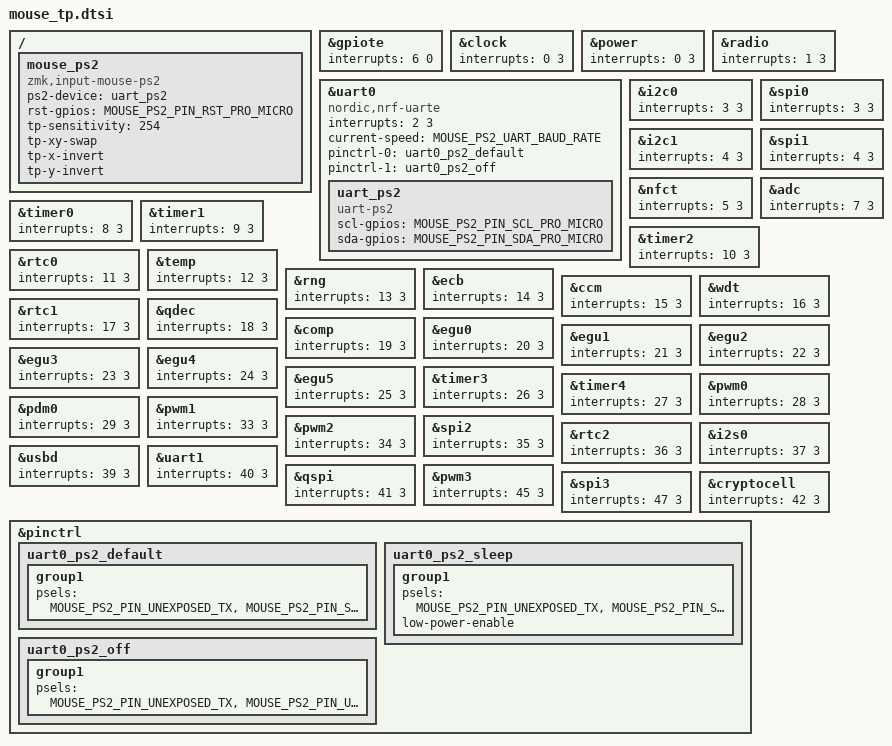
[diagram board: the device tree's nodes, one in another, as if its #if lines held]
#ifdef HAS_MOUSE_TP
  #include <dt-bindings/zmk/mouse.h>
  #include <dt-bindings/zmk/mouse_settings.h>
  #include <behaviors/mouse_keys.dtsi>
  #include <behaviors/mouse_setting.dtsi>
/*
 * PS/2 Mouse / Trackpoint - User Configuration
 *
 * Enable PS/2 drivers on this side of the keyboard.
 * It MUST be the central half. If you connected your TP or mouse to the
 * left side, then move the following content to `your_keyboard_left.overlay`
 *
 * You also need to adjust `Kconfig.defconfig` and configure that this side
 * is the central side.
 *
 */

#define MOUSE_PS2_DRIVER_UART


// Configure the SCL and SDA pins using the`&pro_micro` notation.
//
// If possible, try to choose the blue high frequency pins to avoid
// bluetooth interference.
//
// It will still work even if you pick low frequency pins, but there is a risk
// that the trackpoint could cause bluetooth interference.
//
// On the nice!nano documentation these are green DX pins:
// https://nicekeyboards.com/docs/nice-nano/pinout-schematic
//
// The ideal pins are...
//   - D1 and D0 for clock and data, because they are high frequency.
//   - D8, D9, D16 or D10 for the trackpoint reset pin, because it doesn't
//     need to be high frequency (only needed if you are not using a reset
//     circuit)
//
//RP2040 mod kazubu
// clock gp23 -> 16
// data  gp22 -> 15

// But on the yk_do52pro keyboard the trackpoint is connected to 16 and 15 
// in my I swapped clock and data to be compatible with rp2040 pioj
#define MOUSE_PS2_PIN_SCL_PRO_MICRO <&pro_micro 16 GPIO_ACTIVE_HIGH>
#define MOUSE_PS2_PIN_SDA_PRO_MICRO <&pro_micro 15 GPIO_ACTIVE_HIGH>

// Configure the Power-On-Reset pin
//
// Uncomment and configure this pin if you have an extra free pin and want the
// controller to perform the Power-On-Reset sequence, which many trackpoints
// require.
//
// You don't need this if you are not using a trackpoint or if you have a
// trackpoint reset circuit.
//
// It's ok to use a low-frequency pin for this.
//yk_do52pro has reset circuit
//#define MOUSE_PS2_PIN_RST_PRO_MICRO <&pro_micro 9 GPIO_ACTIVE_HIGH>


// Configure SDA pin using the pinctrl notation
//
// Now configure SDA pin using the pinctrl notation. Make sure to use the same
// pin as in the pro micro notation, but convert it to the pinctrl notation.
//
// For the nice!nano you can find it on their pinout schematic, next to the
// pins, in the blue or violet boxes, with a format like `PX.YY` (P0.09).
//
// Enter it like `X, Y` without leading zeroes.
//h
// Examples:
//      D1  - P0.06: 0, 6
// 		D0  - P0.08: 0, 8
//		D15 - P1.13: 1, 13
//		D16 - P0.10: 0, 10
//		D10 - P0.09: 0, 9
//
// We don't define the SCL pin, because UART uses a baud rate instead of
// a clock pin.
#define MOUSE_PS2_PIN_SDA_PINCTRL <NRF_PSEL(UART_RX, 1, 13)>

// Configure UART BAUD Rate
//
// TLDR WARNING:
// Most likely you won't need to adjust this. So leave it at the default value
// of 14,400 and test if your mouse or trackpoint works.
//
// If it doesn't work, try using the GPIO version of the driver. If it works
// with the GPIO driver, then try using the UART driver with the BAUD rates
// 19,200 and 9,600.
//
// So far, all the trackpoints, which the community tested, worked with the
// 14,400 rate.
//
// Explanation what this is:
//
// PS/2 uses a clock pin to syncronize data transmissions. UART on the
// other hand uses a pre-defined frequency (baud rate).
//
// Fortunately, one of the available baud rates is very close to the
// frequency used in IBM/Lenovo trackpoints.
//
// You can find other configurable baud rates here:
// https://docs.zephyrproject.org/latest/build/dts/api/bindings/serial/nordic,nrf-uarte.html
//
// You can also measure the frequency of your mouse/TP using a $5 logic
// analyzer from AliExpress.
//
// Actual frequency of PS/2 trackpoint: 67us
// Corresponding baud rate: 14,925
//
// Closest available baud rate in zephyr: 14,400
// Corresponding cycle length: 69.44 microseconds
//
// Calculations:
//
// Convert cycle length in microseconds into baud:
// 1 / PS2_CYCLE_LENGTH * 1000000 =  BAUD
// 1 / 67 * 1000000 = 14,925 BAUD
//
// Convert baud into cycle length:
// 1 / BAUD * 1000000 = CYCLE_LEN (in microseconds)
// 1 / 14400 * 1000000 = 69.44
//
// Most likely values
//
// The PS/2 protocol specifies that devices must use a clock line
// frequency in the range of 10 - 16.7 kHz.
//
// Most trackpoints seem to operate at around 14-15kHz.
//
// Therefore, the most likely values to try are:
//   - 14400 ( 69 us cycle length   /   14.5kHz)
//   -  9600 (100 us cycle length   /   10.0kHz)
//   - 19200 ( 52 us cycle length   /   19kHz)
#define MOUSE_PS2_UART_BAUD_RATE <14400>


/*
 * PS/2 Mouse / Trackpoint - User Configuration if NOT using nice!nano
 *
 * WARNING: Do NOT change this if you are using a nice!nano v2 or clone.
 */

// Unexposed UART pins
// In UART two different pins are used for receiving and transmitting, but PS/2
// uses the same pin for both.
//
// The UART config still requires both pins to be configured. So we use one of
// the nrf52 pins that are not exposed on the nice!nano board.
//
// Do NOT change these if you are using a nice!nano (or a clone of it)
#define MOUSE_PS2_PIN_UNEXPOSED_TX <NRF_PSEL(UART_TX, 0, 27)>
#define MOUSE_PS2_PIN_UNEXPOSED_RX <NRF_PSEL(UART_RX, 0, 28)>


// Adjust GPIO interrupt priority to the highest level.
//
// IMPORTANT TLDR:
// If you are using the nice_nano_v2 board, you don't need to make changes to
// the config below and can leave it as it is.
//
// Explanation of these settings:
//
// PS/2 events must be processed within 30-50us, but frequently bluetooth and
// other interrupts take longer to finish.
//
// Therefore we change the default GPIO priority to the highest level (0) and
// demote all BT interrupt priorities by one level using the kconfig settings:
// - CONFIG_BT_CTLR_LLL_PRIO 1
// - CONFIG_BT_CTLR_ULL_HIGH_PRIO 2
// - CONFIG_BT_CTLR_ULL_LOW_PRIOCONFIG 2
//
// These config options are enabled automatically by the PS2 UART and GPIO
// drivers... so you don't have to enable them manually.
//
// Then we lower the interrupt priority of all other devices by 2 levels using
// the devicetree config below.
//
// This allows the PS/2 interrupts to be triggered faster and reduces
// transmission errors.
//
// If you are using the nice_nano_v2 board, you can reuse my config below.
//
// Otherwise, you can generate the interrupt overrides using this script:
// https://github.com/infused-kim/kb_zmk_ps2_mouse_trackpoint_driver/blob/main/scripts/gen_interrupt_priority_overrides.py
//
// Make sure to do it on a zephyr.dts where the interrupts have not been
// adjusted yet (i.e. a config that doesn't have the the following options
// enabled).
//
// If you are building using a toolchain you can find the zephyr.dts in the
// build directory, which by default is: `app/build/zephyr/zephyr.dts`
//
// If you are building using the github actions, copy the output of the build
// step `xxxx_right - nice_nano_v2 Devicetree file` into a file and run the
// script on it.

// gpiote should have the highest interrupt priority (0)
&gpiote {
    interrupts = < 6 0 >;
};



// All other priorities should be two levels lower than their defaults
// (which is usually 1 and should be demoted to 3)
&clock {
    interrupts = < 0 3 >;
};

&power {
    interrupts = < 0 3 >;
};

&radio {
    interrupts = < 1 3 >;
};

&uart0 {
    interrupts = < 2 3 >;
};

&i2c0 {
    interrupts = < 3 3 >;
};

&spi0 {
    interrupts = < 3 3 >;
};

&i2c1 {
    interrupts = < 4 3 >;
};

&spi1 {
    interrupts = < 4 3 >;
};

&nfct {
    interrupts = < 5 3 >;
};

&adc {
    interrupts = < 7 3 >;
};

&timer0 {
    interrupts = < 8 3 >;
};

&timer1 {
    interrupts = < 9 3 >;
};

&timer2 {
    interrupts = < 10 3 >;
};

&rtc0 {
    interrupts = < 11 3 >;
};

&temp {
    interrupts = < 12 3 >;
};

&rng {
    interrupts = < 13 3 >;
};

&ecb {
    interrupts = < 14 3 >;
};

&ccm {
    interrupts = < 15 3 >;
};

&wdt {
    interrupts = < 16 3 >;
};

&rtc1 {
    interrupts = < 17 3 >;
};

&qdec {
    interrupts = < 18 3 >;
};

&comp {
    interrupts = < 19 3 >;
};

&egu0 {
    interrupts = < 20 3 >;
};

&egu1 {
    interrupts = < 21 3 >;
};

&egu2 {
    interrupts = < 22 3 >;
};

&egu3 {
    interrupts = < 23 3 >;
};

&egu4 {
    interrupts = < 24 3 >;
};

&egu5 {
    interrupts = < 25 3 >;
};

&timer3 {
    interrupts = < 26 3 >;
};

&timer4 {
    interrupts = < 27 3 >;
};

&pwm0 {
    interrupts = < 28 3 >;
};

&pdm0 {
    interrupts = < 29 3 >;
};

&pwm1 {
    interrupts = < 33 3 >;
};

&pwm2 {
    interrupts = < 34 3 >;
};

&spi2 {
    interrupts = < 35 3 >;
};

&rtc2 {
    interrupts = < 36 3 >;
};

&i2s0 {
    interrupts = < 37 3 >;
};

&usbd {
    interrupts = < 39 3 >;
};

&uart1 {
    interrupts = < 40 3 >;
};

&qspi {
    interrupts = < 41 3 >;
};

&pwm3 {
    interrupts = < 45 3 >;
};

&spi3 {
    interrupts = < 47 3 >;
};

&cryptocell {
    interrupts = < 42 3 >;
};

// This define can be used in the keymap file to check whether the device tree
// configs in this file are present to void build errors on the side that does
// not have the mouse or TP
#define MOUSE_PS2_DT_PRESENT

&pinctrl {
	// This pinctrl state is used for receiving
	// For `UART_TX`, set an unused and unexposed pin
	// For `UART_RX`, set the PS/2 SDA pin number
	uart0_ps2_default: uart0_ps2_default {
		group1 {
			psels = MOUSE_PS2_PIN_UNEXPOSED_TX,
					MOUSE_PS2_PIN_SDA_PINCTRL;
		};
	};

	// Set this to the same pins as uart0_ps2_default
	uart0_ps2_sleep: uart0_ps2_sleep {
		group1 {
			psels = MOUSE_PS2_PIN_UNEXPOSED_TX,
					MOUSE_PS2_PIN_SDA_PINCTRL;
			low-power-enable;
		};
	};

	// The nrf52 UART controller is not compatible with the PS/2
	// transmission frame. So the PS/2 UART driver doesn't use UART for
	// transmissions and instead use GPIO bit-banging.
	//
	// When the driver switches to transmit mode, it frees up the SDA pin by
    // switching the UART controller to unexposed/unused pins.
	//
	// Then it configures the GPIO controller to use the SCL and SDA pins
	uart0_ps2_off: uart0_ps2_off {
		group1 {
			psels = MOUSE_PS2_PIN_UNEXPOSED_TX,
					MOUSE_PS2_PIN_UNEXPOSED_RX;
		};
	};
};


#ifdef MOUSE_PS2_DRIVER_UART

    &uart0 {
       
        compatible = "nordic,nrf-uarte";

        current-speed = MOUSE_PS2_UART_BAUD_RATE;
        pinctrl-0 = <&uart0_ps2_default>;
        pinctrl-1 = <&uart0_ps2_off>;

        pinctrl-names = "default", "sleep";

        uart_ps2: uart_ps2 {
          
            compatible = "uart-ps2";
            scl-gpios = MOUSE_PS2_PIN_SCL_PRO_MICRO;
            sda-gpios = MOUSE_PS2_PIN_SDA_PRO_MICRO;
        };
    };

#else

    / {
        gpio_ps2: gpio_ps2 {
            status = "disabled";

            compatible = "gpio-ps2";
            scl-gpios = MOUSE_PS2_PIN_SCL_PRO_MICRO;
            sda-gpios = MOUSE_PS2_PIN_SDA_PRO_MICRO;
        };
    };

#endif


/ {
    mouse_ps2: mouse_ps2 {
        compatible = "zmk,input-mouse-ps2";
        
#ifdef MOUSE_PS2_DRIVER_UART
	    ps2-device = <&uart_ps2>;
#else
	    ps2-device = <&gpio_ps2>;
#endif

#ifdef MOUSE_PS2_PIN_RST_PRO_MICRO
        rst-gpios = MOUSE_PS2_PIN_RST_PRO_MICRO;
#endif
    };
};


 /*
  * Key Behaviors to adjust settings
  */

  // They key codes below can be used to adjust the TP settings at runtime
  // without needing to recompile the firmware.
  //
  // The values will be logged and saved in the config on the controller flash
  // after 60s (CONFIG_ZMK_SETTINGS_SAVE_DEBOUNCE).
  //
  // On boot the settings will be restored again.
  //
  // If you prefer a more explicit way of configuration, you can also hardcode
  // these settings in `&mouse_ps2`.
  //
  // If you set these settings in `&mouse_ps2`, you will still be able to
  // adjust the values during runtime with these key codes, but after
  // restarting the board the values in `&mouse_ps2` will be restored and not
  // the ones stored in the flash using the key codes.


  // How sensitive the trackpoint is
  #define U_MSS_TP_S_I &mms MS_TP_SENSITIVITY_INCR
  #define U_MSS_TP_S_D &mms MS_TP_SENSITIVITY_DECR


  // The maximum speed the trackpoint will accelerate to
  #define U_MSS_TP_V6_I &mms MS_TP_VALUE6_INCR
  #define U_MSS_TP_V6_D &mms MS_TP_VALUE6_DECR


  // I am not quite sure tbh... default seems fine.
  #define U_MSS_TP_NI_I &mms MS_TP_NEG_INERTIA_INCR
  #define U_MSS_TP_NI_D &mms MS_TP_NEG_INERTIA_DECR


  // How hard you have to press to activate the "Press To Select" feature that
  // lets you tap or press on the trackpoint to click.
  //
  // Not all trackpoints support it and you have to enable
  // `tp-press-to-select;` in `&mouse_ps2` first.
  #define U_MSS_TP_PT_I &mms MS_TP_PTS_TH\ESHOLD_INCR
  #define U_MSS_TP_PT_D &mms MS_TP_PTS_THRESHOLD_DECR


  // If you mess up the settings, you can use this key code to clear the
  // settings from flash and re-set the default values on the TP.
  //
  // Make sure to wait at least CONFIG_ZMK_SETTINGS_SAVE_DEBOUNCE seconds (60
  // by default) before restarting the board to ensure the settings are
  // written to flash storage.
  #define U_MSS_RESET   &mms MS_RESET


  // If you prefer to set the settings in `&mouse_ps2`, you can use the key
  // codes above to find the settings you like the most and then press this
  // key code to output the settings to the log.
  //
  // Then you can add those values to `&mouse_ps2`
  #define U_MSS_LOG     &mms MS_LOG


  // Only apply these settings on the side that has the TP connected
  // (usually the right side)
  #ifdef MOUSE_PS2_DT_PRESENT

   /*
    * Mouse Driver Settings
    */

    &mouse_ps2 {

      // How sensitive the TP is (Default: 128)
      tp-sensitivity = <254>;

      // The maximum mouse movement speed the TP will accelarate to
      // (Default: 97)
      // tp-val6-upper-speed = <97>;


      // Negative Inertia (Default: 6)
      // Makes the TP feel more responsive and "overshoot" less.
      // tp-neg-inertia = <6>;


      // Enable clicking by tapping on the TP.
      // Not all TPs support this.
      // tp-press-to-select;
      // tp-press-to-select-threshold = <10>;


      // Adjust axis settings on the TP
      // Works only on some trackpoints, but may be properly considered by the
      // trackpoint's acceleration features (which may or may not have an
      // impact).
      //
      // Alternatively consider achieving the same effect using the
      //  `input-listener` settings below.
       tp-xy-swap;
       tp-x-invert;
       tp-y-invert;


      // Set sampling rate
      //
      // The frequency at which the mouse samples and sends data (in hz).
      // The default rate is 100. You can try lowering it if you experience
      // connection errors.
      //
      // Higher values than 100 are no improvement in my experience, but will
      // increase battery life and potentially errors in transmissions.
      //
      // These values are allowed: 10,20,40,60,80,100,200
      // sampling-rate = <60>;


      // Disables clicking.
      // Useful when using the PS2 GPIO driver that is prone to
      // erros in transmissions to reduce accidental clicks.
      // disable-clicking;


      // Enable scroll wheel
      // For mouse devices supporting the Intellimouse extension. Not relevant
      // for trackpoints
      // scroll-mode;

    };

    // Enable PS/2 Mouse Devices
    // In `your_keyboard_right.overlay` all devices have `status = "disabled"`.
    // So,they are never compiled into the firmware.
    //
    // Here we enable them, but we do it within the #ifdef HAS_MOUSE_TP code
    // block, which prevents compilation and potential build errors when we
    // undefine HAS_MOUSE_TP in corne_tp.keymap
    &mouse_ps2  {
      status = "okay";
    };

    #ifdef MOUSE_PS2_DRIVER_UART

      &uart0 {
        status = "okay";
      };

      &uart_ps2 {
        status="okay";
      };

    #else

      &gpio_ps2  {
        status = "okay";
      };

    #endif  // MOUSE_PS2_DRIVER_UART
  #endif  // MOUSE_PS2_DT_PRESENT
#endif  // HAS_MOUSE_TP


